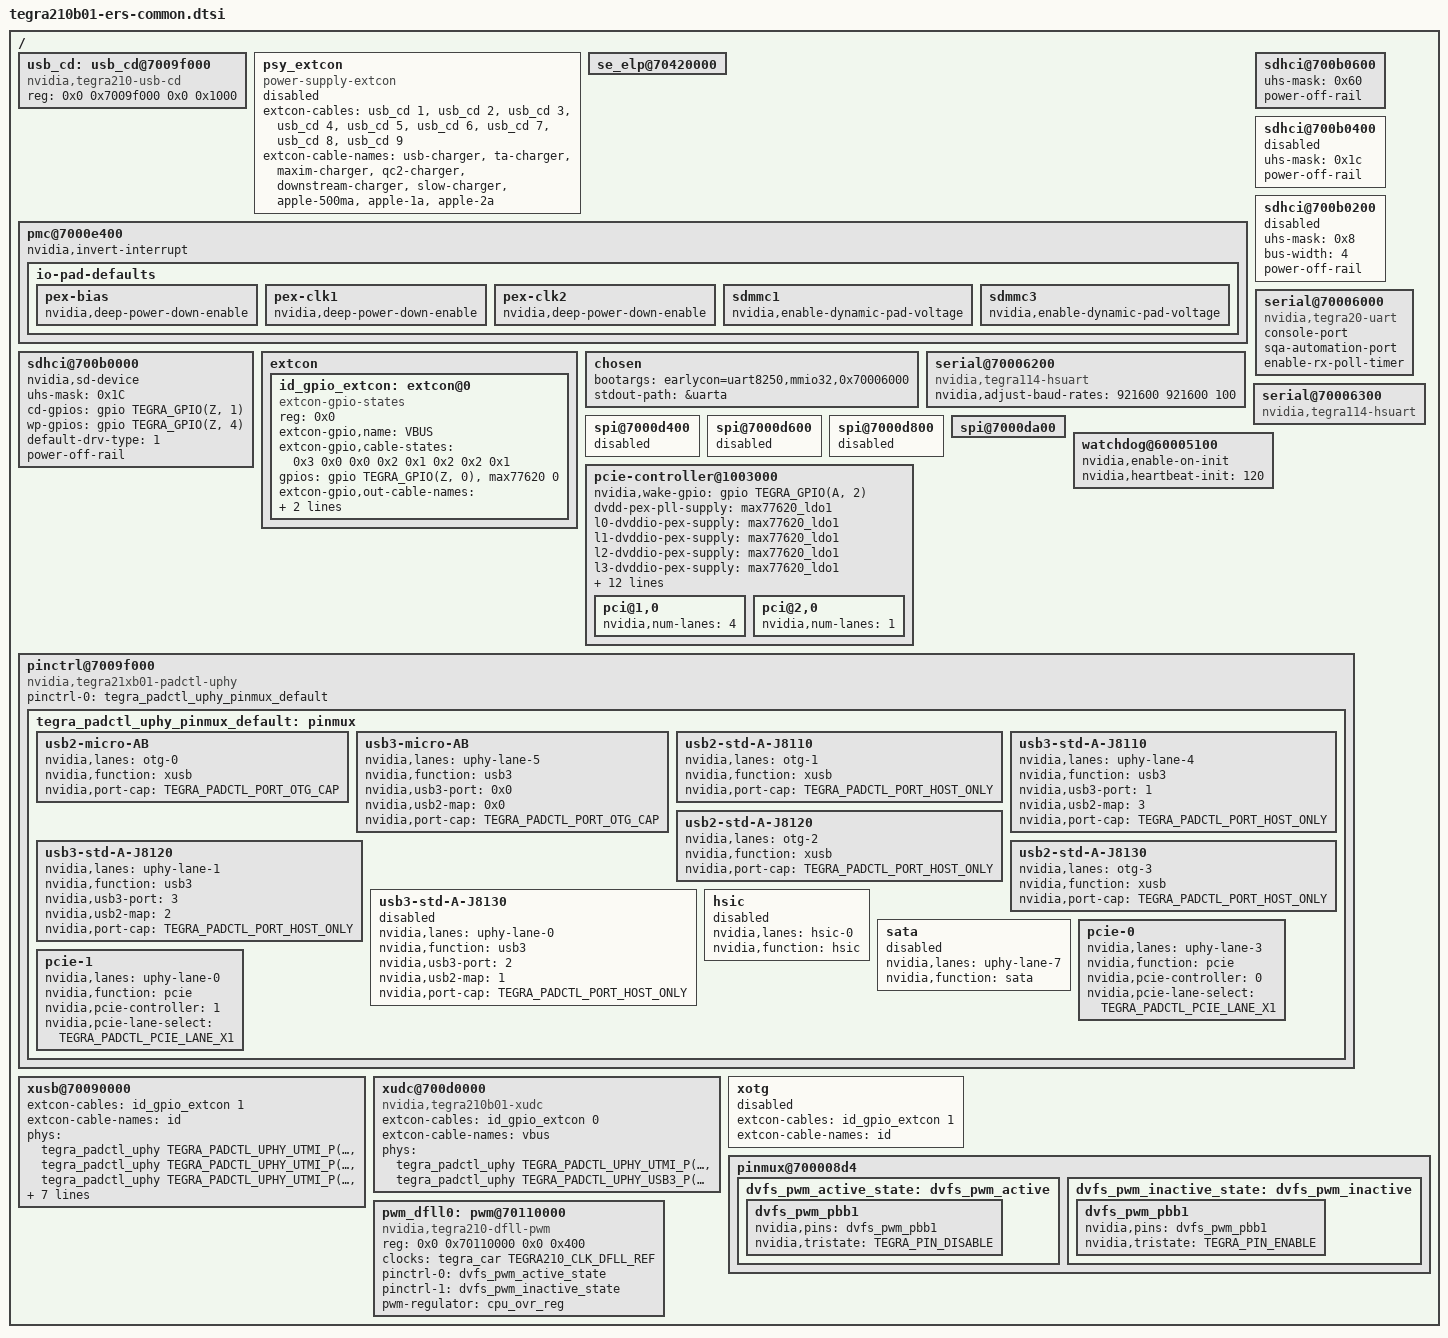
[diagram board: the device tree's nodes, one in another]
/*
 * Copyright (c) 2017, NVIDIA CORPORATION.  All rights reserved.
 *
 * This program is free software; you can redistribute it and/or modify
 * it under the terms of the GNU General Public License as published by
 * the Free Software Foundation; either version 2 of the License, or
 * (at your option) any later version.
 *
 * This program is distributed in the hope that it will be useful, but WITHOUT
 * ANY WARRANTY; without even the implied warranty of MERCHANTABILITY or
 * FITNESS FOR A PARTICULAR PURPOSE.  See the GNU General Public License for
 * more details.
 *
 * You should have received a copy of the GNU General Public License along
 * with this program; if not, write to the Free Software Foundation, Inc.,
 * 51 Franklin Street, Fifth Floor, Boston, MA  02110-1301, USA.
 */

#include <t210b01-soc/tegra210b01-soc-common-platform.dtsi>
#include <tegra210-soc/tegra210-prods.dtsi>
#include <dt-bindings/interrupt-controller/arm-gic.h>
#include <dt-bindings/soc/tegra-pmc.h>
#include <tegra210-soc/tegra210-sdhci.dtsi>

#define EXTCON_NONE             0
#define EXTCON_USB              1
#define EXTCON_USB_HOST         2

/ {
	usb_cd: usb_cd@7009f000 {
		compatible = "nvidia,tegra210-usb-cd";
		reg = <0x0 0x7009f000 0x0 0x1000>;
		#extcon-cells = <1>;
		status = "okay";
	};

	psy_extcon {
		compatible = "power-supply-extcon";
		extcon-cables = <&usb_cd 1 &usb_cd 2 &usb_cd 3
				&usb_cd 4 &usb_cd 5 &usb_cd 6
				&usb_cd 7 &usb_cd 8 &usb_cd 9>;
		extcon-cable-names = "usb-charger", "ta-charger", "maxim-charger",
				"qc2-charger", "downstream-charger", "slow-charger",
				"apple-500ma", "apple-1a", "apple-2a";
		status = "disabled";
	};

	se_elp@70420000 {
		status = "okay";
	};

	pmc@7000e400 {
		nvidia,invert-interrupt;
		io-pad-defaults {
			pex-bias {
				nvidia,deep-power-down-enable;
			};
			pex-clk1 {
				nvidia,deep-power-down-enable;
			};
			pex-clk2 {
				nvidia,deep-power-down-enable;
			};
			sdmmc1 {
				nvidia,enable-dynamic-pad-voltage;
			};
			sdmmc3 {
				nvidia,enable-dynamic-pad-voltage;
			};
		};
	};

	sdhci@700b0600 { /* used for eMMC device*/
		uhs-mask = <0x60>;
		power-off-rail;
		status = "okay";
	};

	sdhci@700b0400 { /* used for SD device*/
		uhs-mask = <0x1c>;
		power-off-rail;
		status = "disabled";
	};

	sdhci@700b0200 { /* used for SDIO device*/
		uhs-mask = <0x8>;
		bus-width = <4>;
		power-off-rail;
		status = "disabled";
	};

	sdhci@700b0000 { /* used for SD device*/
		nvidia,sd-device;
		uhs-mask = <0x1C>;
		cd-gpios = <&gpio TEGRA_GPIO(Z, 1) 0>;
		wp-gpios = <&gpio TEGRA_GPIO(Z, 4) 0>;
		default-drv-type = <1>;
		power-off-rail;
		status = "okay";
	};

	extcon {
		id_gpio_extcon: extcon@0 {
			compatible = "extcon-gpio-states";
			reg = <0x0>;
			extcon-gpio,name = "VBUS";
			extcon-gpio,cable-states = <0x3 0x0
						0x0 0x2
						0x1 0x2
						0x2 0x1>;
			gpios = <&gpio TEGRA_GPIO(Z, 0) 0 &max77620 0 0>;
			extcon-gpio,out-cable-names = <EXTCON_USB EXTCON_USB_HOST EXTCON_NONE>;
			wakeup-source;
			#extcon-cells = <1>;
		};
	};

	chosen {
		bootargs = "earlycon=uart8250,mmio32,0x70006000";
		stdout-path = &uarta;
	};

	serial@70006000 {
		compatible = "nvidia,tegra20-uart", "nvidia,tegra114-hsuart";
		console-port;
		sqa-automation-port;
		enable-rx-poll-timer;
		status = "okay";
	};

	serial@70006200 {
		compatible = "nvidia,tegra114-hsuart";
		dma-names = "tx";
		nvidia,adjust-baud-rates = <921600 921600 100>;
		status = "okay";
	};

	serial@70006300 {
		compatible = "nvidia,tegra114-hsuart";
		status = "okay";
	};

	spi@7000d400 {
		status = "disabled";
	};

	spi@7000d600 {
		status = "disabled";
	};

	spi@7000d800 {
		status = "disabled";
	};

	spi@7000da00 {
		status = "okay";
	};

	watchdog@60005100 {
		nvidia,enable-on-init;
		nvidia,heartbeat-init = <120>;
		status = "okay";
	};

	pcie-controller@1003000 {
		nvidia,wake-gpio = <&gpio TEGRA_GPIO(A, 2) 0>;
		dvdd-pex-pll-supply = <&max77620_ldo1>;
		l0-dvddio-pex-supply = <&max77620_ldo1>;
		l1-dvddio-pex-supply = <&max77620_ldo1>;
		l2-dvddio-pex-supply = <&max77620_ldo1>;
		l3-dvddio-pex-supply = <&max77620_ldo1>;
		l4-dvddio-pex-supply = <&max77620_ldo1>;
		l5-dvddio-pex-supply = <&max77620_ldo1>;
		l6-dvddio-pex-supply = <&max77620_ldo1>;
		hvdd-pex-pll-e-supply = <&max77620_sd3>;
		l0-hvddio-pex-supply = <&max77620_sd3>;
		l1-hvddio-pex-supply = <&max77620_sd3>;
		l2-hvddio-pex-supply = <&max77620_sd3>;
		l3-hvddio-pex-supply = <&max77620_sd3>;
		l4-hvddio-pex-supply = <&max77620_sd3>;
		l5-hvddio-pex-supply = <&max77620_sd3>;
		l6-hvddio-pex-supply = <&max77620_sd3>;
		vddio-pex-ctl-supply = <&max77620_sd3>;
		status = "okay";
		pci@1,0 {
			nvidia,num-lanes = <4>;
			status = "okay";
		};

		pci@2,0 {
			nvidia,num-lanes = <1>;
			status = "okay";
		};
	};

	/* Put common control config here */
	pinctrl@7009f000 {
		compatible = "nvidia,tegra21xb01-padctl-uphy";
		status = "okay";
		pinctrl-0 = <&tegra_padctl_uphy_pinmux_default>;
		pinctrl-names = "default";
		tegra_padctl_uphy_pinmux_default: pinmux {
			usb2-micro-AB {
				nvidia,lanes = "otg-0";
				nvidia,function = "xusb";
				nvidia,port-cap =
					<TEGRA_PADCTL_PORT_OTG_CAP>;
			};
			usb3-micro-AB {
				nvidia,lanes = "uphy-lane-5";
				nvidia,function = "usb3";
				nvidia,usb3-port = <0x0>;
				nvidia,usb2-map = <0x0>;
				nvidia,port-cap =
					<TEGRA_PADCTL_PORT_OTG_CAP>;
			};
			usb2-std-A-J8110 {
				nvidia,lanes = "otg-1";
				nvidia,function = "xusb";
				nvidia,port-cap =
					<TEGRA_PADCTL_PORT_HOST_ONLY>;
			};
			usb3-std-A-J8110 {
				nvidia,lanes = "uphy-lane-4";
				nvidia,function = "usb3";
				nvidia,usb3-port = <1>;
				nvidia,usb2-map = <3>;
				nvidia,port-cap =
					<TEGRA_PADCTL_PORT_HOST_ONLY>;
			};

			usb2-std-A-J8120 {
				nvidia,lanes = "otg-2";
				nvidia,function = "xusb";
				nvidia,port-cap =
					<TEGRA_PADCTL_PORT_HOST_ONLY>;
			};
			usb3-std-A-J8120 {
				nvidia,lanes = "uphy-lane-1";
				nvidia,function = "usb3";
				nvidia,usb3-port = <3>;
				nvidia,usb2-map = <2>;
				nvidia,port-cap =
					<TEGRA_PADCTL_PORT_HOST_ONLY>;
			};
			usb2-std-A-J8130 {
				nvidia,lanes = "otg-3";
				nvidia,function = "xusb";
				nvidia,port-cap =
					<TEGRA_PADCTL_PORT_HOST_ONLY>;
			};
			usb3-std-A-J8130 {
				nvidia,lanes = "uphy-lane-0";
				nvidia,function = "usb3";
				nvidia,usb3-port = <2>;
				nvidia,usb2-map = <1>;
				nvidia,port-cap =
					<TEGRA_PADCTL_PORT_HOST_ONLY>;
				status = "disabled";
			};
			hsic {
				nvidia,lanes = "hsic-0";
				nvidia,function = "hsic";
				status = "disabled";
			};
			sata {
				nvidia,lanes = "uphy-lane-7";
				nvidia,function = "sata";
				status = "disabled";
			};
			pcie-0 {
				nvidia,lanes = "uphy-lane-3";
				nvidia,function = "pcie";
				nvidia,pcie-controller = <0>;
				nvidia,pcie-lane-select =
					<TEGRA_PADCTL_PCIE_LANE_X1>;
			};
			pcie-1 {
				nvidia,lanes = "uphy-lane-0";
				nvidia,function = "pcie";
				nvidia,pcie-controller = <1>;
				nvidia,pcie-lane-select =
					<TEGRA_PADCTL_PCIE_LANE_X1>;
			};
		};
	};

	xusb@70090000 {
		status = "okay";
		extcon-cables = <&id_gpio_extcon 1>;
		extcon-cable-names = "id";
		#extcon-cells = <1>;
		phys = <&tegra_padctl_uphy TEGRA_PADCTL_UPHY_UTMI_P(0)>,
			<&tegra_padctl_uphy TEGRA_PADCTL_UPHY_UTMI_P(1)>,
			<&tegra_padctl_uphy TEGRA_PADCTL_UPHY_UTMI_P(2)>,
			<&tegra_padctl_uphy TEGRA_PADCTL_UPHY_UTMI_P(3)>,
			<&tegra_padctl_uphy TEGRA_PADCTL_UPHY_USB3_P(0)>,
			<&tegra_padctl_uphy TEGRA_PADCTL_UPHY_USB3_P(1)>,
			<&tegra_padctl_uphy TEGRA_PADCTL_UPHY_USB3_P(2)>;
		phy-names = "utmi-0", "utmi-1", "utmi-2", "utmi-3",
			"usb3-0", "usb3-1", "usb3-2";
		nvidia,pmc-wakeup =
			<&tegra_pmc
				PMC_WAKE_TYPE_EVENT 41 PMC_TRIGGER_TYPE_HIGH>,
			<&tegra_pmc
				PMC_WAKE_TYPE_EVENT 44 PMC_TRIGGER_TYPE_HIGH>;
	};

	xudc@700d0000 {
		compatible = "nvidia,tegra210b01-xudc";
		extcon-cables = <&id_gpio_extcon 0>;
		extcon-cable-names = "vbus";
		#extcon-cells = <1>;
		status = "okay";
		phys =  <&tegra_padctl_uphy TEGRA_PADCTL_UPHY_UTMI_P(0)>,
			<&tegra_padctl_uphy TEGRA_PADCTL_UPHY_USB3_P(0)>;
		phy-names = "usb2", "usb3";
	};

	xotg {
		extcon-cables = <&id_gpio_extcon 1>;
		extcon-cable-names = "id";
		#extcon-cells = <1>;
		status = "disabled";
	};

	pinmux@700008d4 {
		dvfs_pwm_active_state: dvfs_pwm_active {
			dvfs_pwm_pbb1 {
				nvidia,pins = "dvfs_pwm_pbb1";
				nvidia,tristate = <TEGRA_PIN_DISABLE>;
			};
		};

		dvfs_pwm_inactive_state: dvfs_pwm_inactive {
			dvfs_pwm_pbb1 {
				nvidia,pins = "dvfs_pwm_pbb1";
				nvidia,tristate = <TEGRA_PIN_ENABLE>;
			};
		};
	};

	pwm_dfll0: pwm@70110000 {
		compatible = "nvidia,tegra210-dfll-pwm";
		reg = <0x0 0x70110000 0x0 0x400>;
		clocks = <&tegra_car TEGRA210_CLK_DFLL_REF>;
		clock-names = "ref";
		pinctrl-names = "dvfs_pwm_enable", "dvfs_pwm_disable";
		pinctrl-0 = <&dvfs_pwm_active_state>;
		pinctrl-1 = <&dvfs_pwm_inactive_state>;
		#pwm-cells = <2>;
		pwm-regulator = <&cpu_ovr_reg>;
		status = "okay";
	};
};
